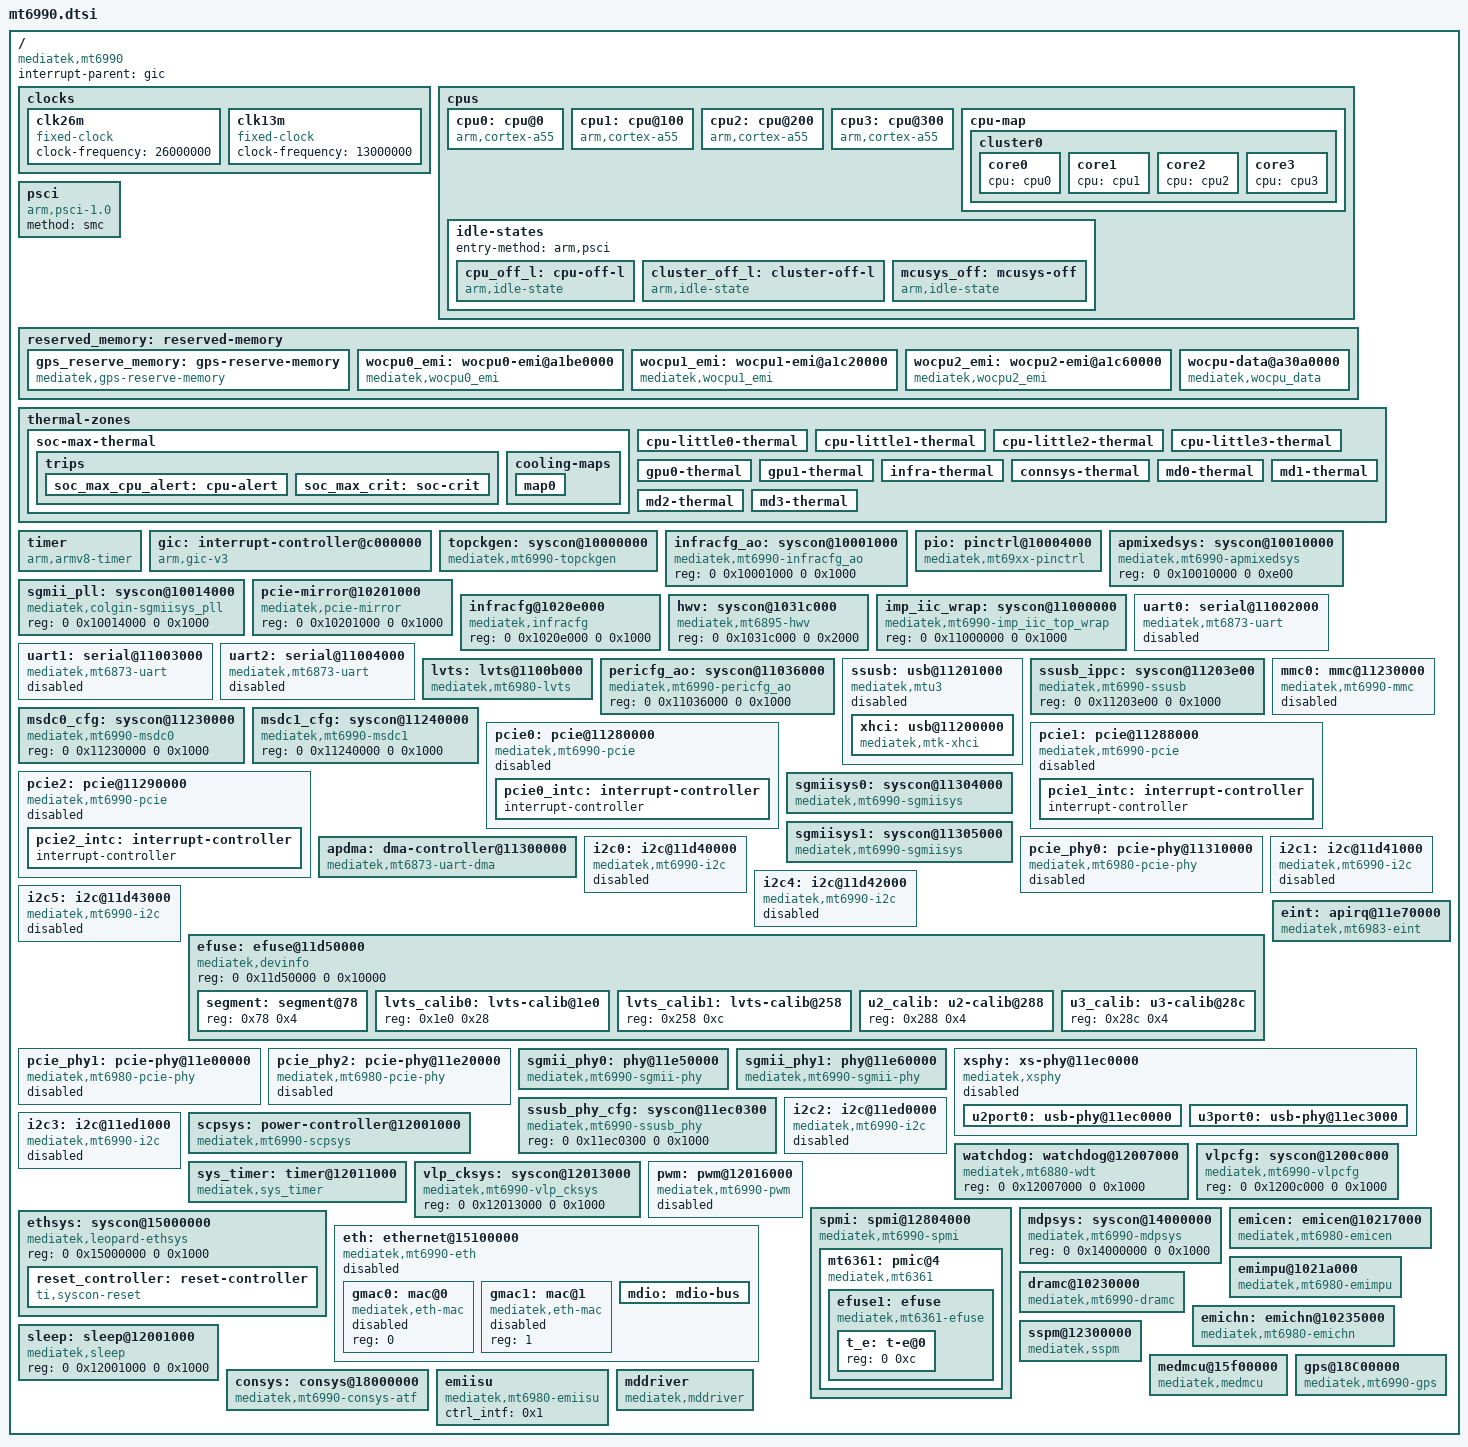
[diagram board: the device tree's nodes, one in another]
// SPDX-License-Identifier: GPL-2.0-only
/*
 * MediaTek MT6990 (T830) SoC
 *
 * Written from the device tree the SoftBank Air 6 stock firmware boots with. It
 * describes the blocks that drivers in this tree use, the nodes those refer to,
 * and the nodes the bootloader (LK) fills in at boot.
 */

#include <dt-bindings/clock/mt6990-clk.h>
#include <dt-bindings/gpio/gpio.h>
#include <dt-bindings/interrupt-controller/arm-gic.h>
#include <dt-bindings/interrupt-controller/irq.h>
#include <dt-bindings/power/mt6990-power.h>
#include <dt-bindings/reset/ti-syscon.h>
#include <dt-bindings/thermal/thermal.h>

/ {
	compatible = "mediatek,mt6990";
	interrupt-parent = <&gic>;
	#address-cells = <2>;
	#size-cells = <2>;

	/*
	 * Devices sit directly under the root, without a "soc" simple-bus: LK patches
	 * several nodes by absolute path, so every path of the stock tree is kept.
	 */

	clocks {
		clk26m: clk26m {
			compatible = "fixed-clock";
			clock-frequency = <26000000>;
			#clock-cells = <0>;
		};

		clk13m: clk13m {
			compatible = "fixed-clock";
			clock-frequency = <13000000>;
			#clock-cells = <0>;
		};
	};

	cpus {
		#address-cells = <1>;
		#size-cells = <0>;

		cpu0: cpu@0 {
			compatible = "arm,cortex-a55";
			reg = <0>;
			device_type = "cpu";
			enable-method = "psci";
			clock-frequency = <1701000000>;
			cpu-idle-states = <&cpu_off_l>, <&cluster_off_l>, <&mcusys_off>;
			#cooling-cells = <2>;
		};

		cpu1: cpu@100 {
			compatible = "arm,cortex-a55";
			reg = <0x100>;
			device_type = "cpu";
			enable-method = "psci";
			clock-frequency = <1701000000>;
			cpu-idle-states = <&cpu_off_l>, <&cluster_off_l>, <&mcusys_off>;
			#cooling-cells = <2>;
		};

		cpu2: cpu@200 {
			compatible = "arm,cortex-a55";
			reg = <0x200>;
			device_type = "cpu";
			enable-method = "psci";
			clock-frequency = <1701000000>;
			cpu-idle-states = <&cpu_off_l>, <&cluster_off_l>, <&mcusys_off>;
			#cooling-cells = <2>;
		};

		cpu3: cpu@300 {
			compatible = "arm,cortex-a55";
			reg = <0x300>;
			device_type = "cpu";
			enable-method = "psci";
			clock-frequency = <1701000000>;
			cpu-idle-states = <&cpu_off_l>, <&cluster_off_l>, <&mcusys_off>;
			#cooling-cells = <2>;
		};

		cpu-map {
			cluster0 {
				core0 {
					cpu = <&cpu0>;
				};

				core1 {
					cpu = <&cpu1>;
				};

				core2 {
					cpu = <&cpu2>;
				};

				core3 {
					cpu = <&cpu3>;
				};
			};
		};

		idle-states {
			entry-method = "arm,psci";

			cpu_off_l: cpu-off-l {
				compatible = "arm,idle-state";
				local-timer-stop;
				entry-latency-us = <50>;
				exit-latency-us = <100>;
				min-residency-us = <1600>;
				arm,psci-suspend-param = <0x10001>;
			};

			cluster_off_l: cluster-off-l {
				compatible = "arm,idle-state";
				local-timer-stop;
				entry-latency-us = <100>;
				exit-latency-us = <250>;
				min-residency-us = <2100>;
				arm,psci-suspend-param = <0x1010001>;
			};

			mcusys_off: mcusys-off {
				compatible = "arm,idle-state";
				local-timer-stop;
				entry-latency-us = <450>;
				exit-latency-us = <600>;
				min-residency-us = <4000>;
				arm,psci-suspend-param = <0x1010002>;
			};
		};
	};

	psci {
		compatible = "arm,psci-1.0";
		method = "smc";
	};

	reserved_memory: reserved-memory {
		ranges;
		#address-cells = <2>;
		#size-cells = <2>;

		gps_reserve_memory: gps-reserve-memory {
			compatible = "mediatek,gps-reserve-memory";
			no-map;
			size = <0 0x60000>;
			alignment = <0 0x10000>;
			alloc-ranges = <0 0x40000000 0 0x80000000>;
		};

		wocpu0_emi: wocpu0-emi@a1be0000 {
			compatible = "mediatek,wocpu0_emi";
			reg = <0 0xa1be0000 0 0x40000>;
			no-map;
			shared = <0>;
		};

		wocpu1_emi: wocpu1-emi@a1c20000 {
			compatible = "mediatek,wocpu1_emi";
			reg = <0 0xa1c20000 0 0x40000>;
			no-map;
			shared = <0>;
		};

		wocpu2_emi: wocpu2-emi@a1c60000 {
			compatible = "mediatek,wocpu2_emi";
			reg = <0 0xa1c60000 0 0x40000>;
			no-map;
			shared = <0>;
		};

		wocpu-data@a30a0000 {
			compatible = "mediatek,wocpu_data";
			reg = <0 0xa30a0000 0 0xf00000>;
			no-map;
			shared = <1>;
		};
	};

	thermal-zones {
		soc-max-thermal {
			polling-delay = <100>;
			polling-delay-passive = <50>;
			thermal-sensors = <&lvts 0>;

			trips {
				soc_max_cpu_alert: cpu-alert {
					temperature = <95000>;
					hysteresis = <2000>;
					type = "passive";
				};

				soc_max_crit: soc-crit {
					temperature = <115000>;
					hysteresis = <2000>;
					type = "critical";
				};
			};

			cooling-maps {
				map0 {
					trip = <&soc_max_cpu_alert>;
					cooling-device = <&cpu0 THERMAL_NO_LIMIT THERMAL_NO_LIMIT>,
					                 <&cpu1 THERMAL_NO_LIMIT THERMAL_NO_LIMIT>,
					                 <&cpu2 THERMAL_NO_LIMIT THERMAL_NO_LIMIT>,
					                 <&cpu3 THERMAL_NO_LIMIT THERMAL_NO_LIMIT>;
					contribution = <1024>;
				};
			};
		};

		cpu-little0-thermal {
			polling-delay = <0>;
			polling-delay-passive = <0>;
			thermal-sensors = <&lvts 1>;
		};

		cpu-little1-thermal {
			polling-delay = <0>;
			polling-delay-passive = <0>;
			thermal-sensors = <&lvts 2>;
		};

		cpu-little2-thermal {
			polling-delay = <0>;
			polling-delay-passive = <0>;
			thermal-sensors = <&lvts 3>;
		};

		cpu-little3-thermal {
			polling-delay = <0>;
			polling-delay-passive = <0>;
			thermal-sensors = <&lvts 4>;
		};

		gpu0-thermal {
			polling-delay = <0>;
			polling-delay-passive = <0>;
			thermal-sensors = <&lvts 5>;
		};

		gpu1-thermal {
			polling-delay = <0>;
			polling-delay-passive = <0>;
			thermal-sensors = <&lvts 6>;
		};

		infra-thermal {
			polling-delay = <0>;
			polling-delay-passive = <0>;
			thermal-sensors = <&lvts 7>;
		};

		connsys-thermal {
			polling-delay = <0>;
			polling-delay-passive = <0>;
			thermal-sensors = <&lvts 8>;
		};

		md0-thermal {
			polling-delay = <0>;
			polling-delay-passive = <0>;
			thermal-sensors = <&lvts 9>;
		};

		md1-thermal {
			polling-delay = <0>;
			polling-delay-passive = <0>;
			thermal-sensors = <&lvts 10>;
		};

		md2-thermal {
			polling-delay = <0>;
			polling-delay-passive = <0>;
			thermal-sensors = <&lvts 11>;
		};

		md3-thermal {
			polling-delay = <0>;
			polling-delay-passive = <0>;
			thermal-sensors = <&lvts 12>;
		};
	};

	timer {
		compatible = "arm,armv8-timer";
		interrupt-parent = <&gic>;
		interrupts = <GIC_PPI 13 IRQ_TYPE_LEVEL_HIGH>,
		             <GIC_PPI 14 IRQ_TYPE_LEVEL_HIGH>,
		             <GIC_PPI 11 IRQ_TYPE_LEVEL_HIGH>,
		             <GIC_PPI 10 IRQ_TYPE_LEVEL_HIGH>;
		clock-frequency = <13000000>;
	};

	gic: interrupt-controller@c000000 {
		compatible = "arm,gic-v3";
		reg = <0 0xc000000 0 0x40000>, <0 0xc040000 0 0x200000>;
		interrupt-parent = <&gic>;
		interrupt-controller;
		interrupts = <GIC_PPI 9 IRQ_TYPE_LEVEL_HIGH>;
		#interrupt-cells = <3>;
		#address-cells = <2>;
		#size-cells = <2>;
		#redistributor-regions = <1>;
	};

	topckgen: syscon@10000000 {
		compatible = "mediatek,mt6990-topckgen", "syscon";
		reg = <0 0x10000000 0 0x1000>;
		#clock-cells = <1>;
		mediatek,hardware-voter = <&hwv>;
	};

	infracfg_ao: syscon@10001000 {
		compatible = "mediatek,mt6990-infracfg_ao", "syscon";
		reg = <0 0x10001000 0 0x1000>;
		#clock-cells = <1>;
	};

	pio: pinctrl@10004000 {
		compatible = "mediatek,mt69xx-pinctrl";
		reg = <0 0x10004000 0 0x1000>,
		      <0 0x11c00000 0 0x1000>,
		      <0 0x11c10000 0 0x1000>,
		      <0 0x11d00000 0 0x1000>,
		      <0 0x11d10000 0 0x1000>,
		      <0 0x11d20000 0 0x1000>,
		      <0 0x11d30000 0 0x1000>,
		      <0 0x11e80000 0 0x1000>,
		      <0 0x11e90000 0 0x1000>,
		      <0 0x11eb0000 0 0x1000>;
		reg-names = "gpio",
		            "iocfg_rt_8",
		            "iocfg_rt_9",
		            "iocfg_bm_4",
		            "iocfg_bm_5",
		            "iocfg_bm_6",
		            "iocfg_bm_7",
		            "iocfg_lt_0",
		            "iocfg_lt_1",
		            "iocfg_lt_3";
		gpio-controller;
		gpio-ranges = <&pio 0 0 0xe2>;
		interrupt-controller;
		#gpio-cells = <2>;
		#interrupt-cells = <2>;
		mediatek,eint = <&eint>;
	};

	apmixedsys: syscon@10010000 {
		compatible = "mediatek,mt6990-apmixedsys", "syscon";
		reg = <0 0x10010000 0 0xe00>;
		#clock-cells = <1>;
	};

	sgmii_pll: syscon@10014000 {
		compatible = "mediatek,colgin-sgmiisys_pll", "syscon";
		reg = <0 0x10014000 0 0x1000>;
	};

	pcie-mirror@10201000 {
		compatible = "mediatek,pcie-mirror";
		reg = <0 0x10201000 0 0x1000>;
	};

	infracfg@1020e000 {
		compatible = "mediatek,infracfg";
		reg = <0 0x1020e000 0 0x1000>;
	};

	hwv: syscon@1031c000 {
		compatible = "mediatek,mt6895-hwv", "syscon";
		reg = <0 0x1031c000 0 0x2000>;
	};

	imp_iic_wrap: syscon@11000000 {
		compatible = "mediatek,mt6990-imp_iic_top_wrap", "syscon";
		reg = <0 0x11000000 0 0x1000>;
		#clock-cells = <1>;
	};

	uart0: serial@11002000 {
		compatible = "mediatek,mt6873-uart", "mediatek,mt6577-uart";
		reg = <0 0x11002000 0 0x1000>;
		interrupts = <GIC_SPI 232 IRQ_TYPE_LEVEL_HIGH>;
		clocks = <&clk26m>, <&pericfg_ao CLK_PERAO_UART0>;
		clock-names = "baud", "bus";
		dmas = <&apdma 0>, <&apdma 1>;
		dma-names = "tx", "rx";
		status = "disabled";
	};

	uart1: serial@11003000 {
		compatible = "mediatek,mt6873-uart", "mediatek,mt6577-uart";
		reg = <0 0x11003000 0 0x1000>, <0 0x11036b90 0 0x20>;
		interrupts = <GIC_SPI 233 IRQ_TYPE_LEVEL_HIGH>;
		clocks = <&clk26m>, <&pericfg_ao CLK_PERAO_UART1>;
		clock-names = "baud", "bus";
		dmas = <&apdma 2>, <&apdma 3>;
		dma-names = "tx", "rx";
		status = "disabled";
	};

	uart2: serial@11004000 {
		compatible = "mediatek,mt6873-uart", "mediatek,mt6577-uart";
		reg = <0 0x11004000 0 0x1000>;
		interrupts = <GIC_SPI 234 IRQ_TYPE_LEVEL_HIGH>;
		clocks = <&clk26m>, <&pericfg_ao CLK_PERAO_UART2>;
		clock-names = "baud", "bus";
		dmas = <&apdma 4>, <&apdma 5>;
		dma-names = "tx", "rx";
		status = "disabled";
	};

	lvts: lvts@1100b000 {
		compatible = "mediatek,mt6980-lvts";
		reg = <0 0x1100b000 0 0x1000>, <0 0x1100c000 0 0x1000>;
		interrupt-parent = <&gic>;
		interrupts = <GIC_SPI 264 IRQ_TYPE_LEVEL_HIGH>, <GIC_SPI 265 IRQ_TYPE_LEVEL_HIGH>;
		clocks = <&pericfg_ao CLK_PERAO_PTP_THERM_MCU_BCLK>,
		         <&pericfg_ao CLK_PERAO_PTP_THERM_MCU_SYS>,
		         <&pericfg_ao CLK_PERAO_PTP_THERM_BCLK>,
		         <&pericfg_ao CLK_PERAO_PTP_THERM_SYS>;
		clock-names = "lvts_clk1", "lvts_clk2", "lvts_clk3", "lvts_clk4";
		nvmem-cells = <&lvts_calib0>, <&lvts_calib1>;
		nvmem-cell-names = "e_data1", "e_data2";
		#thermal-sensor-cells = <1>;
	};

	pericfg_ao: syscon@11036000 {
		compatible = "mediatek,mt6990-pericfg_ao", "syscon";
		reg = <0 0x11036000 0 0x1000>;
		#clock-cells = <1>;
	};

	ssusb: usb@11201000 {
		compatible = "mediatek,mtu3";
		reg = <0 0x11201000 0 0x2e00>,
		      <0 0x11203e00 0 0x100>,
		      <0 0x12001000 0 0x1000>,
		      <0 0x11036000 0 0x1000>;
		reg-names = "mac", "ippc", "spm", "pericfg";
		ranges;
		interrupts = <GIC_SPI 274 IRQ_TYPE_LEVEL_HIGH>;
		phys = <&u2port0 3>, <&u3port0 4>;
		clocks = <&pericfg_ao CLK_PERAO_USB_SYS>, <&pericfg_ao CLK_PERAO_USB_XCHI>;
		clock-names = "sys_ck", "ref_ck";
		maximum-speed = "super-speed-plus";
		power-domains = <&scpsys MT6990_POWER_DOMAIN_SSUSB_TOP>;
		#address-cells = <2>;
		#size-cells = <2>;
		mediatek,usb3-drd;
		mediatek,gen1-txdeemph;
		status = "disabled";

		xhci: usb@11200000 {
			compatible = "mediatek,mtk-xhci";
			reg = <0 0x11200000 0 0x1000>;
			reg-names = "mac";
			interrupts = <GIC_SPI 275 IRQ_TYPE_LEVEL_HIGH>;
			clocks = <&clk26m>;
			clock-names = "sys_ck";
		};
	};

	ssusb_ippc: syscon@11203e00 {
		compatible = "mediatek,mt6990-ssusb", "syscon";
		reg = <0 0x11203e00 0 0x1000>;
		#clock-cells = <1>;
	};

	msdc0_cfg: syscon@11230000 {
		compatible = "mediatek,mt6990-msdc0", "syscon";
		reg = <0 0x11230000 0 0x1000>;
		#clock-cells = <1>;
	};

	mmc0: mmc@11230000 {
		compatible = "mediatek,mt6990-mmc";
		reg = <0 0x11230000 0 0x1000>, <0 0x11f00000 0 0x1000>;
		interrupts = <GIC_SPI 260 IRQ_TYPE_LEVEL_HIGH>;
		clocks = <&pericfg_ao CLK_PERAO_MSDC50_SCAN>,
		         <&pericfg_ao CLK_PERAO_MSDC50_HCLK>,
		         <&pericfg_ao CLK_PERAO_MSDC0_AXI_MASTER>,
		         <&pericfg_ao CLK_PERAO_MSDC0_AHB_SLAVE>;
		clock-names = "source", "hclk", "axi_cg", "ahb_cg";
		#address-cells = <1>;
		#size-cells = <0>;
		status = "disabled";
	};

	msdc1_cfg: syscon@11240000 {
		compatible = "mediatek,mt6990-msdc1", "syscon";
		reg = <0 0x11240000 0 0x1000>;
		#clock-cells = <1>;
	};

	pcie0: pcie@11280000 {
		compatible = "mediatek,mt6990-pcie";
		reg = <0 0x11280000 0 0x2000>;
		reg-names = "pcie-mac";
		ranges = <0x82000000 0 0x30000000 0 0x30000000 0 0x10000000>;
		interrupts = <GIC_SPI 288 IRQ_TYPE_LEVEL_HIGH>;
		bus-range = <0 255>;
		phys = <&pcie_phy0>;
		phy-names = "pcie-phy";
		clocks = <&pericfg_ao CLK_PERAO_PERI2PCIE0__TX>,
		         <&vlpcfg CLK_VLPCFG_PCIE_TL_32K>,
		         <&vlpcfg CLK_VLPCFG_PCIE_TL_26M>,
		         <&vlpcfg CLK_VLPCFG_PCIE_TL_96M>,
		         <&vlpcfg CLK_VLPCFG_PCIE_TL_ULPOSC>,
		         <&vlpcfg CLK_VLPCFG_PCIE_REF_CK_26M>,
		         <&vlpcfg CLK_VLPCFG_PCIE_AXI250>,
		         <&vlpcfg CLK_VLPCFG_PCIE_SRAM_26M>,
		         <&vlp_cksys CLK_VLP_CK_TL_VLP_SEL>;
		power-domains = <&scpsys MT6990_POWER_DOMAIN_PCIE0>;
		interrupt-map-mask = <0 0 0 0x7>;
		interrupt-map = <0 0 0 1 &pcie0_intc 0>,
		                <0 0 0 2 &pcie0_intc 1>,
		                <0 0 0 3 &pcie0_intc 2>,
		                <0 0 0 4 &pcie0_intc 3>;
		#address-cells = <3>;
		#size-cells = <2>;
		#interrupt-cells = <1>;
		linux,pci-domain = <0>;
		status = "disabled";

		pcie0_intc: interrupt-controller {
			interrupt-controller;
			#address-cells = <0>;
			#interrupt-cells = <1>;
		};
	};

	pcie1: pcie@11288000 {
		compatible = "mediatek,mt6990-pcie";
		reg = <0 0x11288000 0 0x2000>;
		reg-names = "pcie-mac";
		ranges = <0x82000000 0 0x40000000 0 0x40000000 0 0x4000000>;
		interrupts = <GIC_SPI 278 IRQ_TYPE_LEVEL_HIGH>;
		bus-range = <0 255>;
		phys = <&pcie_phy1>;
		phy-names = "pcie-phy";
		clocks = <&pericfg_ao CLK_PERAO_PCIE_2LX1_TL>,
		         <&pericfg_ao CLK_PERAO_PCIE_2LX1_REF>,
		         <&pericfg_ao CLK_PERAO_PCIE_2LX1_AXI>,
		         <&pericfg_ao CLK_PERAO_PCIE_2LX1_AHB>,
		         <&pericfg_ao CLK_PERAO_PCIE_2LX1_26M>,
		         <&topckgen CLK_TOP_TL_SEL>,
		         <&topckgen CLK_TOP_PCIE_250M_SEL>;
		power-domains = <&scpsys MT6990_POWER_DOMAIN_PCIE1>;
		interrupt-map-mask = <0 0 0 0x7>;
		interrupt-map = <0 0 0 1 &pcie1_intc 0>,
		                <0 0 0 2 &pcie1_intc 1>,
		                <0 0 0 3 &pcie1_intc 2>,
		                <0 0 0 4 &pcie1_intc 3>;
		#address-cells = <3>;
		#size-cells = <2>;
		#interrupt-cells = <1>;
		linux,pci-domain = <1>;
		status = "disabled";

		pcie1_intc: interrupt-controller {
			interrupt-controller;
			#address-cells = <0>;
			#interrupt-cells = <1>;
		};
	};

	pcie2: pcie@11290000 {
		compatible = "mediatek,mt6990-pcie";
		reg = <0 0x11290000 0 0x2000>;
		reg-names = "pcie-mac";
		ranges = <0x82000000 0 0x44000000 0 0x44000000 0 0x4000000>;
		interrupts = <GIC_SPI 279 IRQ_TYPE_LEVEL_HIGH>;
		bus-range = <0 255>;
		phys = <&pcie_phy2>;
		phy-names = "pcie-phy";
		clocks = <&pericfg_ao CLK_PERAO_PCIE_2LX2_TL>,
		         <&pericfg_ao CLK_PERAO_PCIE_2LX2_REF>,
		         <&pericfg_ao CLK_PERAO_PCIE_2LX2_AXI>,
		         <&pericfg_ao CLK_PERAO_PCIE_2LX2_AHB>,
		         <&pericfg_ao CLK_PERAO_PCIE_2LX2_26M>,
		         <&topckgen CLK_TOP_TL_SEL>,
		         <&topckgen CLK_TOP_PCIE_250M_SEL>;
		power-domains = <&scpsys MT6990_POWER_DOMAIN_PCIE2>;
		interrupt-map-mask = <0 0 0 0x7>;
		interrupt-map = <0 0 0 1 &pcie2_intc 0>,
		                <0 0 0 2 &pcie2_intc 1>,
		                <0 0 0 3 &pcie2_intc 2>,
		                <0 0 0 4 &pcie2_intc 3>;
		#address-cells = <3>;
		#size-cells = <2>;
		#interrupt-cells = <1>;
		linux,pci-domain = <2>;
		status = "disabled";

		pcie2_intc: interrupt-controller {
			interrupt-controller;
			#address-cells = <0>;
			#interrupt-cells = <1>;
		};
	};

	apdma: dma-controller@11300000 {
		compatible = "mediatek,mt6873-uart-dma", "mediatek,mt6577-uart-dma";
		reg = <0 0x11300400 0 0x80>,
		      <0 0x11300480 0 0x80>,
		      <0 0x11300500 0 0x80>,
		      <0 0x11300580 0 0x80>,
		      <0 0x11300600 0 0x80>,
		      <0 0x11300680 0 0x80>;
		interrupts = <GIC_SPI 244 IRQ_TYPE_LEVEL_HIGH>,
		             <GIC_SPI 245 IRQ_TYPE_LEVEL_HIGH>,
		             <GIC_SPI 246 IRQ_TYPE_LEVEL_HIGH>,
		             <GIC_SPI 247 IRQ_TYPE_LEVEL_HIGH>,
		             <GIC_SPI 248 IRQ_TYPE_LEVEL_HIGH>,
		             <GIC_SPI 249 IRQ_TYPE_LEVEL_HIGH>;
		dma-requests = <6>;
		dma-bits = <34>;
		clocks = <&clk26m>;
		#dma-cells = <1>;
	};

	sgmiisys0: syscon@11304000 {
		compatible = "mediatek,mt6990-sgmiisys", "mediatek,colgin-sgmiisys_0", "syscon";
		reg = <0 0x11304000 0 0x1000>;
		phys = <&sgmii_phy0>;
		phy-names = "sgmii";
		#clock-cells = <1>;
		mediatek,physpeed = "2500";
	};

	sgmiisys1: syscon@11305000 {
		compatible = "mediatek,mt6990-sgmiisys", "mediatek,colgin-sgmiisys_1", "syscon";
		reg = <0 0x11305000 0 0x1000>;
		phys = <&sgmii_phy1>;
		phy-names = "sgmii";
		#clock-cells = <1>;
		mediatek,physpeed = "2500";
	};

	pcie_phy0: pcie-phy@11310000 {
		compatible = "mediatek,mt6980-pcie-phy";
		reg = <0 0x11310000 0 0x10000>;
		reg-names = "sif";
		phy-id = <0>;
		power-domains = <&scpsys MT6990_POWER_DOMAIN_PCIE0>;
		#address-cells = <2>;
		#size-cells = <2>;
		#phy-cells = <0>;
		status = "disabled";
	};

	i2c0: i2c@11d40000 {
		compatible = "mediatek,mt6990-i2c", "mediatek,mt8188-i2c";
		reg = <0 0x11d40000 0 0x1000>, <0 0x11300080 0 0x80>;
		interrupts = <GIC_SPI 368 IRQ_TYPE_LEVEL_HIGH>;
		clocks = <&imp_iic_wrap CLK_IMP_IIC_TOP_WRAP_I2C0>, <&pericfg_ao CLK_PERAO_AP_DMA_HCLK>;
		clock-names = "main", "dma";
		clock-div = <1>;
		clock-frequency = <400000>;
		#address-cells = <1>;
		#size-cells = <0>;
		status = "disabled";
	};

	i2c1: i2c@11d41000 {
		compatible = "mediatek,mt6990-i2c", "mediatek,mt8188-i2c";
		reg = <0 0x11d41000 0 0x1000>, <0 0x11300100 0 0x80>;
		interrupts = <GIC_SPI 369 IRQ_TYPE_LEVEL_HIGH>;
		clocks = <&imp_iic_wrap CLK_IMP_IIC_TOP_WRAP_I2C1>, <&pericfg_ao CLK_PERAO_AP_DMA_HCLK>;
		clock-names = "main", "dma";
		clock-div = <1>;
		clock-frequency = <400000>;
		#address-cells = <1>;
		#size-cells = <0>;
		status = "disabled";
	};

	i2c4: i2c@11d42000 {
		compatible = "mediatek,mt6990-i2c", "mediatek,mt8188-i2c";
		reg = <0 0x11d42000 0 0x1000>, <0 0x11300280 0 0x80>;
		interrupts = <GIC_SPI 372 IRQ_TYPE_LEVEL_HIGH>;
		clocks = <&imp_iic_wrap CLK_IMP_IIC_TOP_WRAP_I2C4>, <&pericfg_ao CLK_PERAO_AP_DMA_HCLK>;
		clock-names = "main", "dma";
		clock-div = <1>;
		clock-frequency = <400000>;
		#address-cells = <1>;
		#size-cells = <0>;
		status = "disabled";
	};

	i2c5: i2c@11d43000 {
		compatible = "mediatek,mt6990-i2c", "mediatek,mt8188-i2c";
		reg = <0 0x11d43000 0 0x1000>, <0 0x11300300 0 0x80>;
		interrupts = <GIC_SPI 373 IRQ_TYPE_LEVEL_HIGH>;
		clocks = <&imp_iic_wrap CLK_IMP_IIC_TOP_WRAP_I2C5>, <&pericfg_ao CLK_PERAO_AP_DMA_HCLK>;
		clock-names = "main", "dma";
		clock-div = <1>;
		clock-frequency = <400000>;
		#address-cells = <1>;
		#size-cells = <0>;
		status = "disabled";
	};

	efuse: efuse@11d50000 {
		compatible = "mediatek,devinfo";
		reg = <0 0x11d50000 0 0x10000>;
		#address-cells = <1>;
		#size-cells = <1>;

		segment: segment@78 {
			reg = <0x78 0x4>;
		};

		lvts_calib0: lvts-calib@1e0 {
			reg = <0x1e0 0x28>;
		};

		lvts_calib1: lvts-calib@258 {
			reg = <0x258 0xc>;
		};

		u2_calib: u2-calib@288 {
			reg = <0x288 0x4>;
		};

		u3_calib: u3-calib@28c {
			reg = <0x28c 0x4>;
		};
	};

	pcie_phy1: pcie-phy@11e00000 {
		compatible = "mediatek,mt6980-pcie-phy";
		reg = <0 0x11e00000 0 0x10000>;
		reg-names = "sif";
		phy-id = <1>;
		power-domains = <&scpsys MT6990_POWER_DOMAIN_PCIE1>;
		#address-cells = <2>;
		#size-cells = <2>;
		#phy-cells = <0>;
		status = "disabled";
	};

	pcie_phy2: pcie-phy@11e20000 {
		compatible = "mediatek,mt6980-pcie-phy";
		reg = <0 0x11e20000 0 0x10000>;
		reg-names = "sif";
		phy-id = <2>;
		power-domains = <&scpsys MT6990_POWER_DOMAIN_PCIE2>;
		#address-cells = <2>;
		#size-cells = <2>;
		#phy-cells = <0>;
		status = "disabled";
	};

	sgmii_phy0: phy@11e50000 {
		compatible = "mediatek,mt6990-sgmii-phy";
		reg = <0 0x11e50000 0 0x10000>;
		power-domains = <&scpsys MT6990_POWER_DOMAIN_SGMII_TOP_0>;
		power-domain-names = "sgmii-top";
		#phy-cells = <0>;
		mediatek,sgmii-pll = <&sgmii_pll>;
		mediatek,spm = <&scpsys>;
		mediatek,sgmii-id = <0>;
	};

	sgmii_phy1: phy@11e60000 {
		compatible = "mediatek,mt6990-sgmii-phy";
		reg = <0 0x11e60000 0 0x10000>;
		power-domains = <&scpsys MT6990_POWER_DOMAIN_SGMII_TOP_1>;
		power-domain-names = "sgmii-top";
		#phy-cells = <0>;
		mediatek,sgmii-pll = <&sgmii_pll>;
		mediatek,spm = <&scpsys>;
		mediatek,sgmii-id = <1>;
	};

	eint: apirq@11e70000 {
		compatible = "mediatek,mt6983-eint";
		reg = <0 0x11e70000 0 0x1000>,
		      <0 0x11c30000 0 0x1000>,
		      <0 0x11d70000 0 0x1000>,
		      <0 0x1201e000 0 0x1000>;
		interrupts = <GIC_SPI 160 IRQ_TYPE_LEVEL_HIGH>;
		mediatek,total-pin-number = <237>;
		mediatek,instance-num = <4>;
		mediatek,pins = <0 2 0 1
		                 1 2 1 1
		                 2 2 2 1
		                 3 2 3 1
		                 4 2 4 1
		                 5 2 5 1
		                 6 2 6 1
		                 7 2 7 1
		                 8 2 8 1
		                 9 2 9 1
		                 10 2 10 1
		                 11 2 11 1
		                 12 2 12 1
		                 13 2 13 1
		                 14 2 14 1
		                 15 2 15 1
		                 16 2 16 1
		                 17 2 17 1
		                 18 2 18 1
		                 19 2 19 1
		                 20 2 20 1
		                 21 2 21 1
		                 22 2 22 1
		                 23 2 23 1
		                 24 2 24 1
		                 25 2 25 1
		                 26 2 26 1
		                 27 2 27 1
		                 28 0 0 1
		                 29 0 1 1
		                 30 0 2 1
		                 31 0 3 1
		                 32 0 4 1
		                 35 0 5 1
		                 36 0 6 1
		                 37 0 7 1
		                 38 0 8 1
		                 44 0 9 1
		                 45 0 10 1
		                 46 0 11 1
		                 47 0 12 1
		                 48 2 28 1
		                 49 2 29 1
		                 50 2 30 1
		                 51 2 31 1
		                 52 2 32 1
		                 53 2 33 1
		                 54 2 34 1
		                 55 2 35 1
		                 56 2 36 1
		                 57 2 37 1
		                 58 2 38 1
		                 59 2 39 1
		                 60 2 40 1
		                 61 2 41 1
		                 62 2 42 1
		                 63 2 43 1
		                 64 2 44 1
		                 65 2 45 1
		                 66 2 46 1
		                 67 2 47 1
		                 68 2 48 1
		                 69 2 49 1
		                 70 2 50 1
		                 73 2 51 1
		                 74 2 52 1
		                 75 2 53 1
		                 76 2 54 1
		                 77 2 55 1
		                 78 2 56 1
		                 79 2 57 1
		                 80 2 58 1
		                 81 2 59 1
		                 82 2 60 1
		                 83 2 61 1
		                 84 2 62 1
		                 85 2 63 1
		                 86 2 64 1
		                 87 2 65 1
		                 88 2 66 1
		                 89 2 67 1
		                 90 2 68 1
		                 91 2 69 1
		                 92 2 70 1
		                 93 2 71 1
		                 94 2 72 1
		                 95 2 73 1
		                 96 2 74 1
		                 97 2 75 1
		                 98 2 76 1
		                 99 2 77 1
		                 100 2 78 1
		                 101 2 79 1
		                 102 2 80 1
		                 103 2 81 1
		                 104 2 82 1
		                 105 2 83 1
		                 106 2 84 1
		                 107 2 85 1
		                 108 2 86 1
		                 109 2 87 1
		                 110 2 88 1
		                 111 2 89 1
		                 112 2 90 1
		                 113 2 91 1
		                 114 2 92 1
		                 115 2 93 1
		                 116 2 94 1
		                 117 2 95 1
		                 118 2 96 1
		                 119 2 97 1
		                 120 2 98 1
		                 121 2 99 1
		                 122 2 100 1
		                 123 2 101 1
		                 124 2 102 1
		                 125 2 103 1
		                 126 2 104 1
		                 127 2 105 1
		                 128 2 106 1
		                 136 2 107 1
		                 137 2 108 1
		                 138 2 109 1
		                 139 2 110 1
		                 145 2 111 1
		                 152 2 112 1
		                 153 2 113 1
		                 154 2 114 1
		                 155 2 115 1
		                 173 2 116 1
		                 174 2 117 1
		                 175 2 118 1
		                 189 1 0 1
		                 190 1 1 1
		                 191 1 2 1
		                 192 1 3 1
		                 193 1 4 1
		                 194 1 5 1
		                 195 1 6 1
		                 196 1 7 1
		                 197 1 8 1
		                 198 1 9 1
		                 199 1 10 1
		                 200 1 11 1
		                 201 1 12 1
		                 202 1 13 1
		                 203 1 14 1
		                 204 1 15 1
		                 205 1 16 1
		                 206 1 17 1
		                 207 1 18 1
		                 208 1 19 1
		                 209 1 20 1
		                 210 1 21 1
		                 211 1 22 1
		                 212 3 0 0
		                 213 3 1 0
		                 214 3 2 0
		                 215 3 3 0
		                 216 3 7 0
		                 217 3 8 0
		                 218 3 12 0
		                 219 3 13 0
		                 220 3 16 0>;
	};

	xsphy: xs-phy@11ec0000 {
		compatible = "mediatek,xsphy";
		reg = <0 0x11ec3000 0 0x200>;
		ranges;
		#address-cells = <2>;
		#size-cells = <2>;
		mediatek,mt6990-power-sequence;
		status = "disabled";

		u2port0: usb-phy@11ec0000 {
			reg = <0 0x11ec0000 0 0x400>;
			clocks = <&clk26m>;
			clock-names = "ref";
			nvmem-cells = <&u2_calib>;
			nvmem-cell-names = "u2_efuse_data";
			#phy-cells = <1>;
			mediatek,efuse-u2-intr-cal = <0x23>;
			mediatek,efuse-u2-term-cal = <0x8>;
			mediatek,eye-vrt = <2>;
			mediatek,eye-vrt-host = <2>;
			mediatek,discth = <9>;
			mediatek,rev6 = <1>;
			mediatek,sqth = <5>;
		};

		u3port0: usb-phy@11ec3000 {
			reg = <0 0x11ec3400 0 0x500>;
			clocks = <&clk26m>;
			clock-names = "ref";
			nvmem-cells = <&u3_calib>;
			nvmem-cell-names = "u3_efuse_data";
			#phy-cells = <1>;
		};
	};

	ssusb_phy_cfg: syscon@11ec0300 {
		compatible = "mediatek,mt6990-ssusb_phy", "syscon";
		reg = <0 0x11ec0300 0 0x1000>;
		#clock-cells = <1>;
	};

	i2c2: i2c@11ed0000 {
		compatible = "mediatek,mt6990-i2c", "mediatek,mt8188-i2c";
		reg = <0 0x11ed0000 0 0x1000>, <0 0x11300180 0 0x80>;
		interrupts = <GIC_SPI 370 IRQ_TYPE_LEVEL_HIGH>;
		clocks = <&imp_iic_wrap CLK_IMP_IIC_TOP_WRAP_I2C2>, <&pericfg_ao CLK_PERAO_AP_DMA_HCLK>;
		clock-names = "main", "dma";
		clock-div = <1>;
		clock-frequency = <400000>;
		#address-cells = <1>;
		#size-cells = <0>;
		status = "disabled";
	};

	i2c3: i2c@11ed1000 {
		compatible = "mediatek,mt6990-i2c", "mediatek,mt8188-i2c";
		reg = <0 0x11ed1000 0 0x1000>, <0 0x11300200 0 0x80>;
		interrupts = <GIC_SPI 371 IRQ_TYPE_LEVEL_HIGH>;
		clocks = <&imp_iic_wrap CLK_IMP_IIC_TOP_WRAP_I2C3>, <&pericfg_ao CLK_PERAO_AP_DMA_HCLK>;
		clock-names = "main", "dma";
		clock-div = <1>;
		clock-frequency = <400000>;
		#address-cells = <1>;
		#size-cells = <0>;
		status = "disabled";
	};

	scpsys: power-controller@12001000 {
		compatible = "mediatek,mt6990-scpsys", "syscon";
		reg = <0 0x12001000 0 0x1000>;
		infracfg = <&infracfg_ao>;
		vlpcfg = <&vlp_cksys>;
		pericfg = <&pericfg_ao>;
		clocks = <&topckgen CLK_TOP_MM_SEL>,
		         <&topckgen CLK_TOP_NETSYS_SEL>,
		         <&topckgen CLK_TOP_NETSYS_WED_MCU_SEL>,
		         <&topckgen CLK_TOP_NETSYS_MED_MCU_SEL>,
		         <&topckgen CLK_TOP_NETSYS_500M_SEL>,
		         <&topckgen CLK_TOP_NETSYS_2X_SEL>,
		         <&mdpsys CLK_MDP_SMI_COMMON>,
		         <&topckgen CLK_TOP_ETH_312P5M_SEL>,
		         <&topckgen CLK_TOP_SNPS_ETH_250M_SEL>,
		         <&topckgen CLK_TOP_SNPS_ETH_62P4M_PTP_SEL>,
		         <&topckgen CLK_TOP_SNPS_ETH_50M_RMII_SEL>,
		         <&vlpcfg CLK_VLPCFG_PCIE_SRAM_26M>;
		clock-names = "disp",
		              "netsys",
		              "wedsys",
		              "medsys",
		              "net500",
		              "net2x",
		              "disp-0",
		              "eth1",
		              "eth2",
		              "eth3",
		              "eth4",
		              "pcie0";
		#power-domain-cells = <1>;
	};

	watchdog: watchdog@12007000 {
		compatible = "mediatek,mt6880-wdt", "mediatek,mt6589-wdt", "syscon", "simple-mfd";
		reg = <0 0x12007000 0 0x1000>;
	};

	vlpcfg: syscon@1200c000 {
		compatible = "mediatek,mt6990-vlpcfg", "syscon";
		reg = <0 0x1200c000 0 0x1000>;
		#clock-cells = <1>;
	};

	sys_timer: timer@12011000 {
		compatible = "mediatek,sys_timer", "mediatek,mt6765-timer";
		reg = <0 0x12011000 0 0x1000>;
		interrupts = <GIC_SPI 128 IRQ_TYPE_LEVEL_HIGH>;
		clocks = <&clk13m>;
	};

	vlp_cksys: syscon@12013000 {
		compatible = "mediatek,mt6990-vlp_cksys", "syscon";
		reg = <0 0x12013000 0 0x1000>;
		#clock-cells = <1>;
	};

	pwm: pwm@12016000 {
		compatible = "mediatek,mt6990-pwm";
		reg = <0 0x12016000 0 0x1000>;
		interrupts = <GIC_SPI 142 IRQ_TYPE_LEVEL_HIGH>;
		clocks = <&vlp_cksys CLK_VLP_CK_PWM_VLP_SEL>,
		         <&vlpcfg CLK_VLPCFG_PWM_CK_CGEN_8>,
		         <&vlpcfg CLK_VLPCFG_PWM_CK_CGEN_1>,
		         <&vlpcfg CLK_VLPCFG_PWM_CK_CGEN_2>,
		         <&vlpcfg CLK_VLPCFG_PWM_CK_CGEN_3>,
		         <&vlpcfg CLK_VLPCFG_PWM_CK_CGEN_4>,
		         <&vlpcfg CLK_VLPCFG_PWM_CK_CGEN_5>,
		         <&vlpcfg CLK_VLPCFG_PWM_CK_CGEN_6>,
		         <&vlpcfg CLK_VLPCFG_PWM_CK_CGEN_7>;
		clock-names = "top", "main", "pwm1", "pwm2", "pwm3", "pwm4", "pwm5", "pwm6", "pwm7";
		#pwm-cells = <2>;
		status = "disabled";
	};

	spmi: spmi@12804000 {
		compatible = "mediatek,mt6990-spmi";
		reg = <0 0x12804000 0 0x8ff>, <0 0x12806000 0 0x120>;
		reg-names = "pmif", "spmimst";
		interrupts-extended = <&gic GIC_SPI 168 IRQ_TYPE_LEVEL_HIGH>,
		                      <&pio 220 IRQ_TYPE_LEVEL_HIGH>;
		interrupt-names = "pmif_irq", "rcs_irq";
		interrupt-controller;
		irq_event_en = <0x80000000 0 0 0 0>;
		clocks = <&vlp_cksys CLK_VLP_CK_PWRAP_ULPOSC_SEL>,
		         <&vlp_cksys CLK_VLP_CK_SPMI_M_MST_SEL>;
		clock-names = "vlp_pmif_clk_mux", "vlp_spmimst_m_clk_mux";
		swinf_ch_start = <10>;
		ap_swinf_no = <2>;
		grpid = <11>;
		#interrupt-cells = <1>;
		#address-cells = <2>;
		#size-cells = <0>;

		mt6361: pmic@4 {
			compatible = "mediatek,mt6361";
			reg = <4 0 11 1>;
			interrupts = <4>;
			interrupt-controller;
			#address-cells = <1>;
			#size-cells = <0>;
			#interrupt-cells = <1>;

			efuse1: efuse {
				compatible = "mediatek,mt6361-efuse";
				#address-cells = <1>;
				#size-cells = <1>;

				t_e: t-e@0 {
					reg = <0 0xc>;
				};
			};

			/* USB ID detection (OTG): not compiled in; no driver for it even in the stock kernel */
#if 0
			extcon_usb_microb {
				compatible = "mediatek,extcon-usb-microb";
				interrupts = <2>;
				interrupt-names = "vdet";
				id-gpio = <&pio 45 GPIO_ACTIVE_HIGH>;
				drvbus-gpio = <&pio 46 GPIO_ACTIVE_HIGH>;
				usb_mode = <0>;

				port {
					extcon_microb_role: endpoint@0 {
						remote-endpoint = <&ssusb_role_microb>;
					};
				};
			};
#endif
		};

		/* Modem (CCCI): not compiled in, see the modem note at the end of this file */
#if 0
		md1_sim1_hot_plug_eint {
			compatible = "mediatek,md1_sim1_hot_plug_eint-eint";
			interrupts = <0 4>;
			debounce = <0 100000>;
			dedicated = <0 0>;
			src_pin = <0 1>;
			sockettype = <0 0>;
			status = "okay";
		};

		md1_sim2_hot_plug_eint {
			compatible = "mediatek,md1_sim2_hot_plug_eint-eint";
			interrupts = <1 8>;
			debounce = <1 100000>;
			dedicated = <1 0>;
			src_pin = <1 2>;
			sockettype = <1 0>;
			status = "okay";
		};

		md1_pmic1_eint {
			compatible = "mediatek,md1_pmic1_eint-eint";
			interrupts = <3 8>;
			debounce = <3 0>;
			dedicated = <3 0>;
			src_pin = <3 3>;
			sockettype = <3 0>;
			status = "okay";
		};

		md_attr {
			compatible = "mediatek,md_attr_node";
			mediatek,md_product_name_model_id = <252645135>;
		};
#endif /* modem */
	};

	mdpsys: syscon@14000000 {
		compatible = "mediatek,mt6990-mdpsys", "syscon";
		reg = <0 0x14000000 0 0x1000>;
		#clock-cells = <1>;
	};

	ethsys: syscon@15000000 {
		compatible = "mediatek,leopard-ethsys", "syscon", "simple-mfd";
		reg = <0 0x15000000 0 0x1000>;
		#address-cells = <1>;
		#size-cells = <1>;
		#clock-cells = <1>;
		#reset-cells = <1>;

		reset_controller: reset-controller {
			compatible = "ti,syscon-reset";
			#reset-cells = <1>;
			ti,reset-bits = <0x34 4 0x34 4 0x34 4 (ASSERT_SET | DEASSERT_CLEAR |
			                 STATUS_SET)>;
		};
	};

	/* The last two interrupts (phy0, phy1) are external PHY lines on GPIO 50 and 52. */
	eth: ethernet@15100000 {
		compatible = "mediatek,mt6990-eth", "syscon";
		reg = <0 0x15100000 0 0x30000>;
		interrupts-extended = <&gic GIC_SPI 407 IRQ_TYPE_LEVEL_HIGH>,
		                      <&gic GIC_SPI 408 IRQ_TYPE_LEVEL_HIGH>,
		                      <&gic GIC_SPI 400 IRQ_TYPE_LEVEL_HIGH>,
		                      <&gic GIC_SPI 401 IRQ_TYPE_LEVEL_HIGH>,
		                      <&gic GIC_SPI 402 IRQ_TYPE_LEVEL_HIGH>,
		                      <&gic GIC_SPI 403 IRQ_TYPE_LEVEL_HIGH>,
		                      <&pio 50 IRQ_TYPE_EDGE_FALLING>,
		                      <&pio 52 IRQ_TYPE_EDGE_FALLING>;
		interrupt-names = "fe-reserved",
		                  "fe1",
		                  "fe2",
		                  "fe-rx1",
		                  "fe-rx2",
		                  "fe-rx3",
		                  "phy0",
		                  "phy1";
		clocks = <&topckgen CLK_TOP_SGMII_0_SEL>,
		         <&topckgen CLK_TOP_SGMII_SBUS_0_SEL>,
		         <&topckgen CLK_TOP_SGMII_1_SEL>,
		         <&topckgen CLK_TOP_SGMII_SBUS_1_SEL>,
		         <&topckgen CLK_TOP_USXGMII_SBUS_0_SEL>,
		         <&topckgen CLK_TOP_USXGMII_SBUS_1_SEL>;
		clock-names = "sgmii_0_sel",
		              "sgmii_sbus_0_sel",
		              "sgmii_1_sel",
		              "sgmii_sbus_1_sel",
		              "usxgmii_sbus_0_sel",
		              "usxgmii_sbus_1_sel";
		#address-cells = <1>;
		#size-cells = <0>;
		mediatek,infracfg = <&infracfg_ao>;
		mediatek,ethsys = <&ethsys>;
		mediatek,sgmiisys = <&sgmiisys0>, <&sgmiisys1>;
		mediatek,sgmii_pll = <&sgmii_pll>;
		status = "disabled";

		gmac0: mac@0 {
			compatible = "mediatek,eth-mac";
			reg = <0>;
			status = "disabled";
		};

		gmac1: mac@1 {
			compatible = "mediatek,eth-mac";
			reg = <1>;
			status = "disabled";
		};

		mdio: mdio-bus {
			#address-cells = <1>;
			#size-cells = <0>;
		};
	};

	/*
	 * Nodes the bootloader (LK) fills in at boot (memory map, DRAM and EMI
	 * settings, firmware handover). Linux has no driver for them, but LK finds
	 * them by path, so their names and unit addresses are kept exactly as in the
	 * stock tree, even where they do not follow the naming rules (upper-case
	 * gps@18C00000; consys, gps and medmcu unit addresses that differ from their
	 * first reg; sleep@12001000 sharing the address of scpsys).
	 */

	emicen: emicen@10217000 {
		compatible = "mediatek,mt6980-emicen", "mediatek,common-emicen";
		reg = <0 0x10217000 0 0x1000>;
		a2d_hash = <1>;
		a2d_disph = <2>;
		mediatek,emi-reg = <&emichn>;
	};

	emimpu@1021a000 {
		compatible = "mediatek,mt6980-emimpu", "mediatek,common-emimpu";
		reg = <0 0x1021a000 0 0x1000>;
		interrupts = <GIC_SPI 338 IRQ_TYPE_LEVEL_HIGH>;
		region_cnt = <0x20>;
		domain_cnt = <16>;
		addr_align = <0x10>;
		ap_region = <0x1f>;
		ap_apc = <5 5 0 5 0 0 6 5 0 0 5 5 5 5 5 5>;
		dump = <496 504 508>;
		clear = <352 0xffffffff 16 512 3 16 496 0x80000000 1>;
		clear_md = <508 0x80000000 1>;
		ctrl_intf = <0x1>;
		slverr = <0>;
		mediatek,emi-reg = <&emicen>;
	};

	dramc@10230000 {
		compatible = "mediatek,mt6990-dramc", "mediatek,common-dramc";
		reg = <0 0x10230000 0 0x2000>,
		      <0 0x10240000 0 0x2000>,
		      <0 0x10234000 0 0x1000>,
		      <0 0x10244000 0 0x1000>,
		      <0 0x10238000 0 0x2000>,
		      <0 0x10248000 0 0x2000>,
		      <0 0x10236000 0 0x2000>,
		      <0 0x10246000 0 0x2000>,
		      <0 0x10006000 0 0x1000>;
		mr4_version = <1>;
		mr4_rg = <144 65535 0>;
		fmeter_version = <2>;
		crystal_freq = <26>;
		pll_id = <3252 256 8>;
		shu_lv = <3252 0x30000 16>;
		shu_of = <1792>;
		sdmpcw = <2312 0x7fff8 3 2344 0x7fff8 3>;
		prediv = <2316 49152 14 2348 49152 14>;
		posdiv = <2316 14336 11 2348 14336 11>;
		ckdiv4 = <2164 4 2 2164 4 2>;
		pll_md = <1860 256 8 1860 256 8>;
		cldiv2 = <2228 2 1 2228 2 1>;
		fbksel = <0x910 0x20 0x5 0x910 0x20 0x5>;
		dqopen = <3476 0x2000000 25 3476 0x2000000 25>;
		ckdiv4_b0 = <5100 4 2 5100 4 2>;
		ckdiv4_ca = <4972 4 2 4972 4 2>;
	};

	emichn: emichn@10235000 {
		compatible = "mediatek,mt6980-emichn", "mediatek,common-emichn";
		reg = <0 0x10235000 0 0x1000>, <0 0x10245000 0 0x1000>;
	};

	sleep: sleep@12001000 {
		compatible = "mediatek,sleep", "syscon";
		reg = <0 0x12001000 0 0x1000>;
	};

	sspm@12300000 {
		compatible = "mediatek,sspm";
		reg = <0 0x12300000 0 0x28000>,
		      <0 0x12340000 0 0x10000>,
		      <0 0x12350000 0 0x100>,
		      <0 0x12351000 0 0x4>,
		      <0 0x12351004 0 0x4>,
		      <0 0x12360000 0 0x100>,
		      <0 0x12361000 0 0x4>,
		      <0 0x12361004 0 0x4>,
		      <0 0x12370000 0 0x100>,
		      <0 0x12371000 0 0x4>,
		      <0 0x12371004 0 0x4>,
		      <0 0x12380000 0 0x100>,
		      <0 0x12381000 0 0x4>,
		      <0 0x12381004 0 0x4>,
		      <0 0x12390000 0 0x100>,
		      <0 0x12391000 0 0x4>,
		      <0 0x12391004 0 0x4>;
		reg-names = "sspm_base",
		            "cfgreg",
		            "mbox0_base",
		            "mbox0_set",
		            "mbox0_clr",
		            "mbox1_base",
		            "mbox1_set",
		            "mbox1_clr",
		            "mbox2_base",
		            "mbox2_set",
		            "mbox2_clr",
		            "mbox3_base",
		            "mbox3_set",
		            "mbox3_clr",
		            "mbox4_base",
		            "mbox4_set",
		            "mbox4_clr";
		interrupts = <GIC_SPI 143 IRQ_TYPE_LEVEL_HIGH>,
		             <GIC_SPI 145 IRQ_TYPE_LEVEL_HIGH>,
		             <GIC_SPI 146 IRQ_TYPE_LEVEL_HIGH>,
		             <GIC_SPI 147 IRQ_TYPE_LEVEL_HIGH>,
		             <GIC_SPI 148 IRQ_TYPE_LEVEL_HIGH>,
		             <GIC_SPI 149 IRQ_TYPE_LEVEL_HIGH>;
		interrupt-names = "ipc", "mbox0", "mbox1", "mbox2", "mbox3", "mbox4";
		sspm_res_ram_start = <0>;
		sspm_res_ram_size = <0x210000>;
	};

	medmcu@15f00000 {
		compatible = "mediatek,medmcu";
		reg = <0 0x15d00000 0 0x20000>,
		      <0 0x15f24000 0 0x1000>,
		      <0 0x15f21000 0 0x1000>,
		      <0 0x15f30000 0 0x1000>,
		      <0 0x15f40000 0 0x1000>,
		      <0 0x15f52000 0 0x1000>,
		      <0 0x15f60000 0 0x40000>,
		      <0 0x15fa5000 0 0x4>,
		      <0 0x15ffb000 0 0x100>,
		      <0 0x15ffb100 0 0x4>,
		      <0 0x15ffb10c 0 0x4>,
		      <0 0x15fa5020 0 0x4>,
		      <0 0x15ffc000 0 0x100>,
		      <0 0x15ffc100 0 0x4>,
		      <0 0x15ffc10c 0 0x4>,
		      <0 0x15fa5024 0 0x4>,
		      <0 0x15ffd000 0 0x100>,
		      <0 0x15ffd100 0 0x4>,
		      <0 0x15ffd10c 0 0x4>,
		      <0 0x15fa5028 0 0x4>,
		      <0 0x15ffe000 0 0x100>,
		      <0 0x15ffe100 0 0x4>,
		      <0 0x15ffe10c 0 0x4>,
		      <0 0x15fa502c 0 0x4>,
		      <0 0x15fff000 0 0x100>,
		      <0 0x15fff100 0 0x4>,
		      <0 0x15fff10c 0 0x4>,
		      <0 0x15fa5030 0 0x4>,
		      <0 0x15b80000 0 0x100>;
		reg-names = "scp_sram_base",
		            "scp_cfgreg",
		            "scp_clkreg",
		            "scp_cfgreg_core0",
		            "scp_cfgreg_core1",
		            "scp_bus_tracker",
		            "scp_l1creg",
		            "scp_cfgreg_sec",
		            "mbox0_base",
		            "mbox0_set",
		            "mbox0_clr",
		            "mbox0_init",
		            "mbox1_base",
		            "mbox1_set",
		            "mbox1_clr",
		            "mbox1_init",
		            "mbox2_base",
		            "mbox2_set",
		            "mbox2_clr",
		            "mbox2_init",
		            "mbox3_base",
		            "mbox3_set",
		            "mbox3_clr",
		            "mbox3_init",
		            "mbox4_base",
		            "mbox4_set",
		            "mbox4_clr",
		            "mbox4_init";
		interrupts = <GIC_SPI 463 IRQ_TYPE_LEVEL_HIGH>,
		             <GIC_SPI 464 IRQ_TYPE_LEVEL_HIGH>,
		             <GIC_SPI 465 IRQ_TYPE_LEVEL_HIGH>,
		             <GIC_SPI 466 IRQ_TYPE_LEVEL_HIGH>,
		             <GIC_SPI 467 IRQ_TYPE_LEVEL_HIGH>;
		interrupt-names = "mbox0", "mbox1", "mbox2", "mbox3", "mbox4";
		core_0 = "enable";
		scp_sramSize = <0x20000>;
		mbox_count = <5>;
		send_table = <0 0 7 3 1 2 4 1 1 5 1 1 6 1 1 11 2 18 13 2 1 15 3 1 16 3 1 17 3 1 18 3
		              1 19 3 1 20 3 1 21 3 1 22 3 2 23 3 2 24 3 2 31 4 34>;
		recv_table = <1 0 2 0 2 0 20 0 7 1 2 0 8 1 10 0 9 1 1 0 10 1 2 0 5 1 1 1 12 2 2 0 14
		              2 2 0 25 3 2 0 26 3 10 0 27 3 1 0 28 3 5 0 29 3 1 0 30 3 2 0 17 3 1 1
		              32 4 30 0>;
		power-domains = <&scpsys MT6990_POWER_DOMAIN_MED>;
		clocks = <&topckgen CLK_TOP_NETSYS_MED_MCU_SEL>;
		clock-names = "medmcu_sel";
		status = "okay";
	};

	consys: consys@18000000 {
		compatible = "mediatek,mt6990-consys-atf";
		reg = <0 0x10001000 0 0xf68>,
		      <0 0x10004000 0 0xa7c>,
		      <0 0x11d20000 0 0xa04>,
		      <0 0x12001000 0 0xfb0>,
		      <0 0x18000000 0 0x470>,
		      <0 0x18001000 0 0x658>,
		      <0 0x18003000 0 0x204>,
		      <0 0x1800e000 0 0x124>,
		      <0 0x18011000 0 0x138>,
		      <0 0x18012000 0 0x98>,
		      <0 0x18020000 0 0x4c>,
		      <0 0x18023000 0 0xe28>,
		      <0 0x1803b000 0 0x18>,
		      <0 0x18040000 0 0x2c>,
		      <0 0x18041000 0 0x140>,
		      <0 0x18042000 0 0x324>,
		      <0 0x1804b000 0 0x414>,
		      <0 0x1804d000 0 0x41c>,
		      <0 0x1804f000 0 0x148>,
		      <0 0x18051000 0 0x1000>,
		      <0 0x18060000 0 0xbf8>,
		      <0 0x18070000 0 0x7004>;
		power-domains = <&scpsys MT6990_POWER_DOMAIN_CONN_ON>;
		emi-addr = <0>;
		emi-size = <0>;
		fw-binary-size = <0x80000>;
		fw-data-size = <0>;
		ap-shared-size = <0x78000>;
		ap-no-perm-size = <0>;
		gps-emi-offset = <0x80000>;
		emi-alignment = <0x10000>;
		emi-max-addr = <0xffffffff>;
		radio-support = "gps";
		tcxo_support = "false";
		#thermal-sensor-cells = <0>;
	};

	gps@18C00000 {
		compatible = "mediatek,mt6990-gps";
		reg = <0 0x18000000 0 0x100000>,
		      <0 0x18c00000 0 0x100000>,
		      <0 0x18d00000 0 0x100000>,
		      <0 0x10003304 0 0x4>,
		      <0 0x1001c000 0 0x4>,
		      <0 0x1001c030 0 0x4>;
		reg-names = "conn_infra_base",
		            "conn_gps_base",
		            "conn_dyn_base",
		            "status_dummy_cr",
		            "tia2_gps_on",
		            "tia2_gps_rc_sel";
		interrupts = <GIC_SPI 380 IRQ_TYPE_LEVEL_HIGH>,
		             <GIC_SPI 381 IRQ_TYPE_LEVEL_HIGH>,
		             <GIC_SPI 382 IRQ_TYPE_LEVEL_HIGH>,
		             <GIC_SPI 383 IRQ_TYPE_LEVEL_HIGH>,
		             <GIC_SPI 384 IRQ_TYPE_LEVEL_HIGH>,
		             <GIC_SPI 385 IRQ_TYPE_LEVEL_HIGH>,
		             <GIC_SPI 386 IRQ_TYPE_LEVEL_HIGH>,
		             <GIC_SPI 387 IRQ_TYPE_LEVEL_HIGH>,
		             <GIC_SPI 388 IRQ_TYPE_LEVEL_HIGH>,
		             <GIC_SPI 389 IRQ_TYPE_EDGE_RISING>,
		             <GIC_SPI 390 IRQ_TYPE_LEVEL_HIGH>;
		memory-region = <&gps_reserve_memory>;
		pmic = <&efuse1>;
		emi-addr = <0>;
	};

	emiisu {
		compatible = "mediatek,mt6980-emiisu", "mediatek,common-emiisu";
		ctrl_intf = <0x1>;
	};

	mddriver {
		compatible = "mediatek,mddriver";
		reg = <0 0xd124000 0 0x2000>;
		interrupts = <GIC_SPI 333 IRQ_TYPE_LEVEL_HIGH>;
		power-domains = <&scpsys MT6990_POWER_DOMAIN_MD>;
		ccci-infracfg = <&infracfg_ao>;
		mediatek,mdhif_type = <2>;
		mediatek,md_id = <0>;
		mediatek,ap_plat_info = <6990>;
		mediatek,md_generation = <6298>;
		mediatek,offset_epon_md1 = <0x44 0x6>;
		mediatek,cldma_capability = <2>;
		mediatek,power_flow_config = <4>;
		mediatek,srclken_o1 = <0>;
	};

	/*
	 * Modem (CCCI, MD1): described from the stock device tree, not compiled in.
	 * The hardware is present, but this tree has no driver for it yet; remove the
	 * #if 0 when one is added. /mddriver and /medmcu stay compiled because LK
	 * writes the modem memory layout into them.
	 */
#if 0
	dpmaif@10011000 {
		compatible = "mediatek,dpmaif";
		reg = <0 0x10011000 0 0x1000>,
		      <0 0x1022d000 0 0x1000>,
		      <0 0x1022c000 0 0x1000>,
		      <0 0x1022e000 0 0x1000>,
		      <0 0x15b14000 0 0x1000>,
		      <0 0x15b38000 0 0x1000>,
		      <0 0x15b13000 0 0x1000>;
		interrupts = <GIC_SPI 209 IRQ_TYPE_LEVEL_HIGH>, <GIC_SPI 456 IRQ_TYPE_LEVEL_HIGH>;
		clocks = <&infracfg_ao CLK_IFRAO_DPMAIF>,
		         <&infracfg_ao CLK_IFRAO_RG_MMW_DPMAIF26M_CK>;
		clock-names = "infra-dpmaif-clk", "infra-dpmaif-rg-mmw-clk";
		mediatek,dpmaif_capability = <6>;
	};

	dpmaif_ao@10011000 {
		compatible = "mediatek,dpmaif_ao";
		reg = <0 0x10011000 0 0x1000>;
	};

	ap_ccif0@10209000 {
		compatible = "mediatek,ap_ccif0";
		reg = <0 0x10209000 0 0x1000>;
		interrupts = <GIC_SPI 258 IRQ_TYPE_LEVEL_HIGH>;
	};

	ccifdriver@10209000 {
		compatible = "mediatek,ccci_ccif";
		reg = <0 0x10209000 0 0x1000>, <0 0x1020a000 0 0x1000>;
		interrupts = <GIC_SPI 184 IRQ_TYPE_LEVEL_HIGH>, <GIC_SPI 185 IRQ_TYPE_LEVEL_HIGH>;
		clocks = <&infracfg_ao CLK_IFRAO_CCIF0>, <&infracfg_ao CLK_IFRAO_CCIF1>;
		clock-names = "infra-ccif0", "infra-ccif1";
		mediatek,sram_size = <0x200>;
	};

	md_ccif0@1020a000 {
		compatible = "mediatek,md_ccif0";
		reg = <0 0x1020a000 0 0x1000>;
	};

	ap_ccif1@1020b000 {
		compatible = "mediatek,ap_ccif1";
		reg = <0 0x1020b000 0 0x1000>;
		interrupts = <GIC_SPI 260 IRQ_TYPE_LEVEL_HIGH>;
	};

	md_ccif1@1020c000 {
		compatible = "mediatek,md_ccif1";
		reg = <0 0x1020c000 0 0x1000>;
	};

	md2md_md2_ccif0@10213000 {
		compatible = "mediatek,md2md_md2_ccif0";
		reg = <0 0x10213000 0 0x1000>;
	};

	infra_dpmaif@1022c000 {
		compatible = "mediatek,infra_dpmaif";
		reg = <0 0x1022c000 0 0x10>;
	};

	ap_ccif2@1023c000 {
		compatible = "mediatek,ap_ccif2";
		reg = <0 0x1023c000 0 0x1000>;
		interrupts = <GIC_SPI 262 IRQ_TYPE_LEVEL_HIGH>;
	};

	md_ccif2@1023d000 {
		compatible = "mediatek,md_ccif2";
		reg = <0 0x1023d000 0 0x1000>;
	};

	ap_ccif3@1023e000 {
		compatible = "mediatek,ap_ccif3";
		reg = <0 0x1023e000 0 0x1000>;
		interrupts = <GIC_SPI 263 IRQ_TYPE_LEVEL_HIGH>;
	};

	md_ccif3@1023f000 {
		compatible = "mediatek,md_ccif3";
		reg = <0 0x1023f000 0 0x1000>;
	};

	ap_ccif4@1024c000 {
		compatible = "mediatek,ap_ccif4";
		reg = <0 0x1024c000 0 0x1000>;
	};

	md_ccif4@1024d000 {
		compatible = "mediatek,md_ccif4";
		reg = <0 0x1024d000 0 0x1000>;
	};

	md_ccif4@1024e000 {
		compatible = "mediatek,md_ccif4";
		reg = <0 0x1024e000 0 0x1000>;
	};

	ap_ccif5@1025c000 {
		compatible = "mediatek,ap_ccif5";
		reg = <0 0x1025c000 0 0x1000>;
	};

	md_ccif5@1025d000 {
		compatible = "mediatek,md_ccif5";
		reg = <0 0x1025d000 0 0x1000>;
	};

	tinsys@10500000 {
		compatible = "mediatek,tinsys";
		reg = <0 0x10500000 0 0>;
	};

	modem_temp_share@12012000 {
		compatible = "mediatek,modem_temp_share";
		reg = <0 0x12012000 0 0x1000>;
	};

	md_rf_ic: md-rf-ic {
		compatible = "mediatek,md-rf";
		#thermal-sensor-cells = <0>;
	};

	mutt {
		compatible = "mediatek,mt6297-md-cooler-mutt";

		mutt_pa1: mutt-pa1 {
			id = <0>;
			#cooling-cells = <2>;
		};

		mutt_pa1_no_ims: mutt-pa1-no-ims {
			id = <0>;
			#cooling-cells = <2>;
		};

		mutt_pa2: mutt-pa2 {
			id = <1>;
			#cooling-cells = <2>;
		};

		mutt_pa2_no_ims: mutt-pa2-no-ims {
			id = <1>;
			#cooling-cells = <2>;
		};
	};

	mutt-cc {
		compatible = "mediatek,md-cooler-mutt_cc";

		mutt-cc1 {
			id = <0>;
			#cooling-cells = <2>;
		};

		mutt-cc2 {
			id = <1>;
			#cooling-cells = <2>;
		};
	};

	ul-control {
		compatible = "mediatek,md-cooler-ul-control";

		ul-control {
			id = <0>;
			#cooling-cells = <2>;
		};
	};

	tx-pwr {
		compatible = "mediatek,md-cooler-tx-pwr";

		tx-pwr-pa1 {
			id = <0>;
			#cooling-cells = <2>;
		};

		tx-pwr-pa2 {
			id = <1>;
			#cooling-cells = <2>;
		};
	};

	scg-off {
		compatible = "mediatek,md-cooler-scg-off";

		scg-off-pa2 {
			id = <1>;
			#cooling-cells = <2>;
		};
	};

	cldma_sys_ap {
		compatible = "mediatek,cldma_sys_ap";
		reg = <0 0x1004a000 0 0x1000>, <0 0x1021e000 0 0x1000>;
		interrupts = <GIC_SPI 285 IRQ_TYPE_LEVEL_HIGH>;
		clock-names = "infra-cldma0-rh";
		mediatek,hif_ids = <1>;
	};
#endif /* modem */
};
